# ATmega3250PA register map
Vendor: Atmel; File version: 1.0
CPU: other r0p0, little endian, no MPU, no FPU, 4 interrupt priority bits
Registers are 8-bit, read-write, reset 0x0 unless marked. A register's access mark holds for its fields unless they carry their own. Offsets are from the block's base; [hi:lo] are bit positions; {n}, {i} and the like mark numbered series.

## BOOT_LOAD — Bootloader
Base 0x00800057
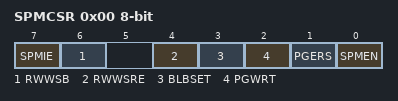
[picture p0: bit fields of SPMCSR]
0x00 SPMCSR — Store Program Memory Control Register
  [7] SPMIE — SPM Interrupt Enable
  [6] RWWSB — Read While Write Section Busy
  [4] RWWSRE — Read While Write section read enable
  [3] BLBSET — Boot Lock Bit Set
  [2] PGWRT — Page Write
  [1] PGERS — Page Erase
  [0] SPMEN — Store Program Memory Enable

## CPU — CPU Registers
Base 0x0080003E
0x00 GPIOR0 — General Purpose IO Register 0
0x0C GPIOR1 — General Purpose IO Register 1
0x0D GPIOR2 — General Purpose IO Register 2
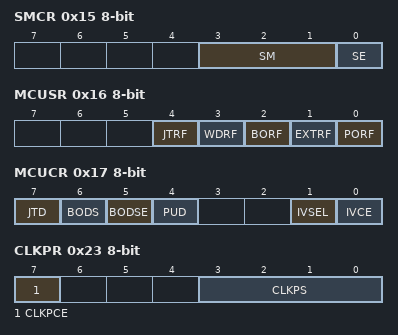
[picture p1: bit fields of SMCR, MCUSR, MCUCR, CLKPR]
0x15 SMCR — Sleep Mode Control Register
  [3:1] SM — Sleep Mode Select bits
    0=IDLE; 1=ADC (ADC Noise Reduction (If Available)); 2=PDOWN (Power Down); 3=PSAVE (Power Save); 6=STDBY (Standby)
  [0] SE — Sleep Enable
0x16 MCUSR — MCU Status Register
  [4] JTRF — JTAG Reset Flag
  [3] WDRF — Watchdog Reset Flag
  [2] BORF — Brown-out Reset Flag
  [1] EXTRF — External Reset Flag
  [0] PORF — Power-on reset flag
0x17 MCUCR — MCU Control Register
  [7] JTD — JTAG Interface Disable
  [6] BODS — BOD Sleep
  [5] BODSE — BOD Sleep Enable
  [4] PUD — Pull-up disable
  [1] IVSEL — Interrupt Vector Select
  [0] IVCE — Interrupt Vector Change Enable
0x23 CLKPR — Clock Prescale Register
  [7] CLKPCE — Clock Prescaler Change Enable
  [3:0] CLKPS — Clock Prescaler Select Bits
    0=1; 1=2; 2=4; 3=8; 4=16; 5=32; 6=64; 7=128; 8=256
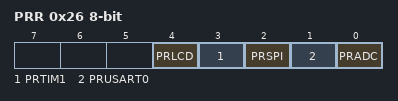
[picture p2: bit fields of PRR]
0x26 PRR — Power Reduction Register
  [4] PRLCD — Power Reduction LCD
  [3] PRTIM1 — Power Reduction Timer/Counter1
  [2] PRSPI — Power Reduction Serial Peripheral Interface
  [1] PRUSART0 — Power Reduction USART
  [0] PRADC — Power Reduction ADC
0x28 OSCCAL — Oscillator Calibration Value
  [7:0] OSCCAL — Oscillator Calibration

## EEPROM
Base 0x0080003F
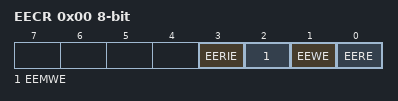
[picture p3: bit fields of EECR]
0x00 EECR — EEPROM Control Register
  [3] EERIE — EEPROM Ready Interrupt Enable
  [2] EEMWE — EEPROM Master Write Enable
  [1] EEWE — EEPROM Write Enable
  [0] EERE — EEPROM Read Enable
0x01 EEDR — EEPROM Data Register
0x02 EEAR 16-bit (reset mask 0xFF) — EEPROM Read/Write Access Bytes

## EXINT — External Interrupts
Base 0x0080003C
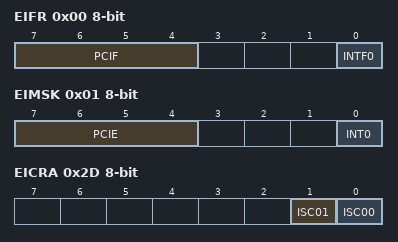
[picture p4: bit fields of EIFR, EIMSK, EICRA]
0x00 EIFR — External Interrupt Flag Register (read-only for debugger)
  [7:4] PCIF — Pin Change Interrupt Flags
  [0] INTF0 — External Interrupt Flag 0
0x01 EIMSK — External Interrupt Mask Register
  [7:4] PCIE — Pin Change Interrupt Enables
  [0] INT0 — External Interrupt Request 0 Enable
0x2D EICRA — External Interrupt Control Register A
  [1] ISC01 — External Interrupt Sense Control 0 Bit 1
  [0] ISC00 — External Interrupt Sense Control 0 Bit 0
    0=LOW_LEVEL_OF_INTX; 1=ANY_LOGICAL_CHANGE_OF_INTX
{0x2F+i} PCMSK{i} (i=0..2) — Pin Change Mask Register {i}
0x37 PCMSK3 — Pin Change Mask Register 3

## JTAG — JTAG Interface
Base 0x00800051
0x00 OCDR — On-Chip Debug Related Register in I/O Memory (write-only for debugger)
0x03 MCUSR — MCU Status Register (read-only for debugger)
  [4] JTRF — JTAG Reset Flag
0x04 MCUCR — MCU Control Register
  [7] JTD — JTAG Interface Disable

## LOCKBIT — Lockbits
Base 0x00800000
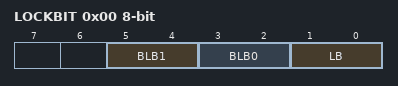
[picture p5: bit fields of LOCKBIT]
0x00 LOCKBIT
  [5:4] BLB1 — Boot Loader Protection Mode
    0=LPM_SPM_DISABLE (LPM and SPM prohibited in Boot Section); 1=LPM_DISABLE (LPM prohibited in Boot Section); 2=SPM_DISABLE (SPM prohibited in Boot Section); 3=NO_LOCK (No lock on SPM and LPM in Boot Section)
  [3:2] BLB0 — Boot Loader Protection Mode
    0=LPM_SPM_DISABLE (LPM and SPM prohibited in Application Section); 1=LPM_DISABLE (LPM prohibited in Application Section); 2=SPM_DISABLE (SPM prohibited in Application Section); 3=NO_LOCK (No lock on SPM and LPM in Application Section)
  [1:0] LB — Memory Lock
    0=PROG_VER_DISABLED (Further programming and verification disabled); 2=PROG_DISABLED (Further programming disabled); 3=NO_LOCK (No memory lock features enabled)
